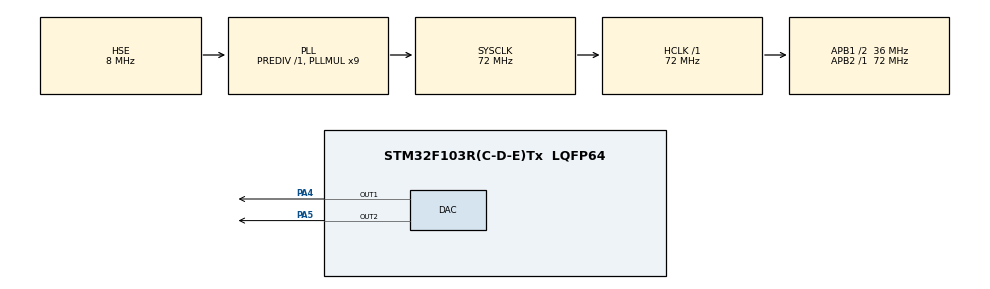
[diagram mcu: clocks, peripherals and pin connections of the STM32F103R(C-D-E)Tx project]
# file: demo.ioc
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Mcu.Family=STM32F1
Mcu.Name=STM32F103R(C-D-E)Tx
Mcu.Package=LQFP64
NVIC.PriorityGroup=NVIC_PRIORITYGROUP_4
PA13.Mode=Serial_Wire
PA13.Signal=SYS_JTMS-SWDIO
PA14.Mode=Serial_Wire
PA14.Signal=SYS_JTCK-SWCLK
PA4.Signal=COMP_DAC1_group
PA5.Signal=COMP_DAC2_group
PD0-OSC_IN.Mode=HSE-External-Oscillator
PD0-OSC_IN.Signal=RCC_OSC_IN
PD1-OSC_OUT.Mode=HSE-External-Oscillator
PD1-OSC_OUT.Signal=RCC_OSC_OUT
ProjectManager.HeapSize=0x200
ProjectManager.StackSize=0x400
ProjectManager.TargetToolchain=MDK-ARM V5
RCC.AHBFreq_Value=72000000
RCC.APB1CLKDivider=RCC_HCLK_DIV2
RCC.APB1Freq_Value=36000000
RCC.APB1TimFreq_Value=72000000
RCC.APB2Freq_Value=72000000
RCC.APB2TimFreq_Value=72000000
RCC.HCLKFreq_Value=72000000
RCC.PLLMUL=RCC_PLL_MUL9
RCC.PLLSourceVirtual=RCC_PLLSOURCE_HSE
RCC.SYSCLKFreq_VALUE=72000000
RCC.SYSCLKSource=RCC_SYSCLKSOURCE_PLLCLK
RCC.USBFreq_Value=72000000
SH.COMP_DAC1_group.0=DAC_OUT1,DAC_OUT1
SH.COMP_DAC2_group.0=DAC_OUT2,DAC_OUT2
board=custom

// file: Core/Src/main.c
/* USER CODE BEGIN Header */
/**
 ******************************************************************************
 * @file           : main.c
 * @brief          : Main program body
 ******************************************************************************
 * @attention
 *
 * <h2><center>&copy; Copyright (c) 2022 STMicroelectronics.
 * All rights reserved.</center></h2>
 *
 * This software component is licensed by ST under BSD 3-Clause license,
 * the "License"; You may not use this file except in compliance with the
 * License. You may obtain a copy of the License at:
 *                        opensource.org/licenses/BSD-3-Clause
 *
 ******************************************************************************
 */
/* USER CODE END Header */
#include "main.h"
#include "dac.h"
#include "gpio.h"

void SystemClock_Config(void);

/* USER CODE BEGIN 0 */

#if 0

// string

static const uint8_t xs[] = {
    2, 2, 22, 22, 2, 22,                     // R
    27, 48, 48, 27, 27, 27, 48, 48, 27, 48,  // 2
    52, 52, 73, 73, 52, 73, 73,              // A
    85, 77, 77, 77, 85, 91, 98, 98, 98, 91,  // U
    102, 102, 102, 123, 102, 123,            // K
};
static const uint8_t ys[] = {
    42, 84, 84, 63, 63, 42,                  // R
    42, 63, 84, 84, 63, 84, 84, 63, 42, 42,  // 2
    42, 84, 84, 63, 63, 63, 42,              // A
    42, 50, 84, 50, 42, 42, 50, 84, 50, 42,  // U
    42, 84, 63, 84, 63, 42,                  // K
};

int16_t idx       = 0;
int16_t prev_idx  = 0;
uint8_t curr_x    = 0;
uint8_t curr_y    = 0;
int16_t dx        = 0;
int16_t dy        = 0;
int8_t  direction = 1;

void next_line()
{
    const uint8_t speed          = 32;
    int8_t        next_direction = direction;
    idx += direction;
    if (idx < 0) {
        idx            = 0;
        next_direction = -direction;
    } else if (idx >= sizeof(xs) / sizeof(xs[0])) {
        idx            = sizeof(xs) / sizeof(xs[0]) - 1;
        next_direction = -direction;
    }

    prev_idx = idx - direction;
    if (prev_idx < 0) {
        prev_idx = sizeof(xs) / sizeof(xs[0]) - 1;
    } else if (prev_idx >= sizeof(xs) / sizeof(xs[0])) {
        prev_idx = 0;
    }

    direction = next_direction;
    curr_x    = xs[prev_idx];
    curr_y    = ys[prev_idx];

    dx        = (((int16_t)xs[idx]) - ((int16_t)xs[prev_idx])) / speed;
    dy        = (((int16_t)ys[idx]) - ((int16_t)ys[prev_idx])) / speed;
    if (dx == 0) {
        if (xs[idx] > xs[prev_idx]) {
            dx = 1;
        } else if (xs[idx] < xs[prev_idx]) {
            dx = -1;
        }
    }

    if (dy == 0) {
        if (ys[idx] > ys[prev_idx]) {
            dy = 1;
        } else if (ys[idx] < ys[prev_idx]) {
            dy = -1;
        }
    }
}

void init()
{
    HAL_DAC_Start(&hdac, DAC_CHANNEL_1);
    HAL_DAC_Start(&hdac, DAC_CHANNEL_2);
    next_line();
    HAL_Delay(1);
}

void loop()
{
    curr_x += dx;
    curr_y += dy;
    if (((dx > 0) && (curr_x > xs[idx])) ||
        ((dx < 0) && (curr_x < xs[idx]))) {
        curr_x = xs[idx];
    }
    if (((dy > 0) && (curr_y > ys[idx])) ||
        ((dy < 0) && (curr_y < ys[idx]))) {
        curr_y = ys[idx];
    }

    uint32_t x = ((uint32_t)curr_x) * 0xFFF / 128;
    uint32_t y = ((uint32_t)curr_y) * 0xFFF / 128;
    HAL_DAC_SetValue(&hdac, DAC_CHANNEL_1, DAC_ALIGN_12B_R, x);
    HAL_DAC_SetValue(&hdac, DAC_CHANNEL_2, DAC_ALIGN_12B_R, y);

    if ((curr_x == xs[idx]) && (curr_y == ys[idx])) {
        next_line();
    }

    HAL_Delay(10);
}

#else

// image

#define ARRAY_SIZE(arr) (sizeof(arr) / sizeof(arr[0]))

static const uint16_t img[3832] = {
    976, 3147, 995, 3147, 1013, 3147, 1032, 3147, 1050, 3147,
    1069, 3147, 1087, 3147, 1105, 3147, 1124, 3147, 1142, 3147,
    1161, 3147, 1179, 3147, 1198, 3147, 1216, 3147, 1235, 3147,
    1253, 3147, 1271, 3147, 1290, 3147, 1308, 3147, 1327, 3147,
    1345, 3147, 1364, 3147, 1382, 3147, 1400, 3147, 1419, 3147,
    1437, 3147, 1456, 3147, 1474, 3147, 1493, 3147, 1511, 3147,
    1529, 3147, 1548, 3147, 1566, 3147, 1585, 3147, 1603, 3147,
    1622, 3147, 1640, 3147, 1658, 3147, 1677, 3147, 1695, 3147,
    1714, 3147, 1732, 3147, 1751, 3147, 1769, 3147, 1788, 3147,
    1806, 3147, 1824, 3147, 1843, 3147, 1861, 3147, 1880, 3147,
    1898, 3147, 1917, 3147, 1935, 3147, 1953, 3147, 1972, 3147,
    1990, 3147, 2009, 3147, 2027, 3147, 2046, 3147, 2064, 3147,
    2082, 3147, 2101, 3147, 2119, 3147, 2138, 3147, 2156, 3147,
    2175, 3147, 2193, 3147, 2211, 3147, 2230, 3147, 2248, 3147,
    2267, 3147, 2285, 3147, 2304, 3147, 2322, 3147, 2341, 3147,
    2359, 3147, 2377, 3147, 2396, 3147, 2414, 3147, 2433, 3147,
    2451, 3147, 2470, 3147, 2488, 3147, 2506, 3147, 2525, 3147,
    2543, 3147, 2562, 3147, 2580, 3147, 2599, 3147, 2617, 3147,
    2635, 3147, 2654, 3147, 2672, 3147, 2691, 3147, 2709, 3147,
    2728, 3147, 2746, 3147, 2764, 3147, 2783, 3147, 2801, 3147,
    2820, 3147, 2838, 3147, 2857, 3147, 2875, 3147, 2894, 3147,
    2912, 3147, 2930, 3147, 2949, 3147, 2967, 3147, 2986, 3147,
    3004, 3147, 3023, 3147, 3041, 3147, 3059, 3147, 3078, 3147,
    3096, 3147, 958, 3122, 3115, 3122, 940, 3098, 3115, 3098,
    940, 3074, 3115, 3074, 940, 3049, 1087, 3049, 1105, 3049,
    1124, 3049, 1142, 3049, 1161, 3049, 1179, 3049, 1198, 3049,
    1216, 3049, 1235, 3049, 1253, 3049, 1271, 3049, 1290, 3049,
    1308, 3049, 1327, 3049, 1345, 3049, 1364, 3049, 1382, 3049,
    1400, 3049, 1419, 3049, 1437, 3049, 1456, 3049, 1474, 3049,
    1493, 3049, 1511, 3049, 1529, 3049, 1548, 3049, 1566, 3049,
    1585, 3049, 1603, 3049, 1622, 3049, 1640, 3049, 1658, 3049,
    1677, 3049, 1695, 3049, 1714, 3049, 1732, 3049, 1751, 3049,
    1769, 3049, 1788, 3049, 1806, 3049, 1824, 3049, 1843, 3049,
    1861, 3049, 1880, 3049, 1898, 3049, 1917, 3049, 1935, 3049,
    1953, 3049, 1972, 3049, 1990, 3049, 2009, 3049, 2027, 3049,
    2046, 3049, 2064, 3049, 2082, 3049, 2101, 3049, 2119, 3049,
    2138, 3049, 2156, 3049, 2175, 3049, 2193, 3049, 2211, 3049,
    2230, 3049, 2248, 3049, 2267, 3049, 2285, 3049, 2304, 3049,
    2322, 3049, 2341, 3049, 2359, 3049, 2377, 3049, 2396, 3049,
    2414, 3049, 2433, 3049, 2451, 3049, 2470, 3049, 2488, 3049,
    2506, 3049, 2525, 3049, 2543, 3049, 2562, 3049, 2580, 3049,
    2599, 3049, 2617, 3049, 2635, 3049, 2654, 3049, 2672, 3049,
    2691, 3049, 2709, 3049, 2728, 3049, 2746, 3049, 2764, 3049,
    2783, 3049, 2801, 3049, 2820, 3049, 2838, 3049, 2857, 3049,
    2875, 3049, 2894, 3049, 2912, 3049, 2930, 3049, 2949, 3049,
    2967, 3049, 2986, 3049, 3004, 3049, 3115, 3049, 940, 3025,
    1069, 3025, 3023, 3025, 3115, 3025, 940, 3000, 1050, 3000,
    3023, 3000, 3115, 3000, 940, 2976, 1050, 2976, 3023, 2976,
    3115, 2976, 940, 2952, 1050, 2952, 3023, 2952, 3115, 2952,
    940, 2927, 1050, 2927, 1179, 2927, 1198, 2927, 1216, 2927,
    1235, 2927, 1253, 2927, 1271, 2927, 1290, 2927, 1308, 2927,
    1327, 2927, 1345, 2927, 1364, 2927, 1382, 2927, 1400, 2927,
    1419, 2927, 1437, 2927, 1456, 2927, 1474, 2927, 1493, 2927,
    1511, 2927, 1529, 2927, 1548, 2927, 1566, 2927, 1585, 2927,
    1603, 2927, 1622, 2927, 1640, 2927, 1658, 2927, 1677, 2927,
    1695, 2927, 1714, 2927, 1732, 2927, 1751, 2927, 1769, 2927,
    1788, 2927, 1806, 2927, 1824, 2927, 1843, 2927, 1861, 2927,
    1880, 2927, 1898, 2927, 1917, 2927, 1935, 2927, 1953, 2927,
    1972, 2927, 1990, 2927, 2009, 2927, 2027, 2927, 2046, 2927,
    2064, 2927, 2082, 2927, 2101, 2927, 2119, 2927, 2138, 2927,
    2156, 2927, 2175, 2927, 2193, 2927, 2211, 2927, 2230, 2927,
    2248, 2927, 2267, 2927, 2285, 2927, 2304, 2927, 2322, 2927,
    2341, 2927, 2359, 2927, 2377, 2927, 2396, 2927, 2414, 2927,
    2433, 2927, 2451, 2927, 2470, 2927, 2488, 2927, 2506, 2927,
    2525, 2927, 2543, 2927, 2562, 2927, 2580, 2927, 2599, 2927,
    2617, 2927, 2635, 2927, 2654, 2927, 2672, 2927, 2691, 2927,
    2709, 2927, 2728, 2927, 2746, 2927, 2764, 2927, 2783, 2927,
    2801, 2927, 2820, 2927, 2838, 2927, 2857, 2927, 2875, 2927,
    2894, 2927, 2912, 2927, 3023, 2927, 3115, 2927, 940, 2903,
    1050, 2903, 1161, 2903, 2930, 2903, 3023, 2903, 3115, 2903,
    940, 2879, 1050, 2879, 1142, 2879, 2930, 2879, 3023, 2879,
    3115, 2879, 940, 2854, 1050, 2854, 1142, 2854, 2930, 2854,
    3023, 2854, 3115, 2854, 940, 2830, 1050, 2830, 1142, 2830,
    2930, 2830, 3023, 2830, 3115, 2830, 940, 2805, 1050, 2805,
    1142, 2805, 2930, 2805, 3023, 2805, 3115, 2805, 940, 2781,
    1050, 2781, 1142, 2781, 2930, 2781, 3023, 2781, 3115, 2781,
    940, 2757, 1050, 2757, 1142, 2757, 2930, 2757, 3023, 2757,
    3115, 2757, 940, 2732, 1050, 2732, 1142, 2732, 1953, 2732,
    1972, 2732, 1990, 2732, 2009, 2732, 2027, 2732, 2046, 2732,
    2064, 2732, 2082, 2732, 2101, 2732, 2119, 2732, 2930, 2732,
    3023, 2732, 3115, 2732, 940, 2708, 1050, 2708, 1142, 2708,
    1861, 2708, 1880, 2708, 1898, 2708, 1917, 2708, 1935, 2708,
    2138, 2708, 2156, 2708, 2175, 2708, 2193, 2708, 2211, 2708,
    2230, 2708, 2930, 2708, 3023, 2708, 3115, 2708, 940, 2683,
    1050, 2683, 1142, 2683, 1769, 2683, 1788, 2683, 1806, 2683,
    1824, 2683, 1843, 2683, 2248, 2683, 2267, 2683, 2285, 2683,
    2304, 2683, 2930, 2683, 3023, 2683, 3115, 2683, 940, 2659,
    1050, 2659, 1142, 2659, 1732, 2659, 1751, 2659, 2322, 2659,
    2341, 2659, 2930, 2659, 3023, 2659, 3115, 2659, 940, 2635,
    1050, 2635, 1142, 2635, 1677, 2635, 1695, 2635, 1714, 2635,
    2359, 2635, 2377, 2635, 2396, 2635, 2930, 2635, 3023, 2635,
    3115, 2635, 940, 2610, 1050, 2610, 1142, 2610, 1640, 2610,
    1658, 2610, 1935, 2610, 1953, 2610, 1972, 2610, 1990, 2610,
    2009, 2610, 2027, 2610, 2046, 2610, 2064, 2610, 2082, 2610,
    2101, 2610, 2119, 2610, 2138, 2610, 2414, 2610, 2433, 2610,
    2930, 2610, 3023, 2610, 3115, 2610, 940, 2586, 1050, 2586,
    1142, 2586, 1603, 2586, 1622, 2586, 1861, 2586, 1880, 2586,
    1898, 2586, 1917, 2586, 2156, 2586, 2175, 2586, 2193, 2586,
    2211, 2586, 2451, 2586, 2470, 2586, 2930, 2586, 3023, 2586,
    3115, 2586, 940, 2561, 1050, 2561, 1142, 2561, 1585, 2561,
    1603, 2561, 1788, 2561, 1806, 2561, 1824, 2561, 1843, 2561,
    2230, 2561, 2248, 2561, 2267, 2561, 2285, 2561, 2470, 2561,
    2488, 2561, 2930, 2561, 3023, 2561, 3115, 2561, 940, 2537,
    1050, 2537, 1142, 2537, 1548, 2537, 1566, 2537, 1751, 2537,
    1769, 2537, 2304, 2537, 2322, 2537, 2506, 2537, 2525, 2537,
    2930, 2537, 3023, 2537, 3115, 2537, 940, 2513, 1050, 2513,
    1142, 2513, 1529, 2513, 1548, 2513, 1714, 2513, 1732, 2513,
    2341, 2513, 2359, 2513, 2377, 2513, 2525, 2513, 2543, 2513,
    2930, 2513, 3023, 2513, 3115, 2513, 940, 2488, 1050, 2488,
    1142, 2488, 1493, 2488, 1511, 2488, 1677, 2488, 1695, 2488,
    2396, 2488, 2414, 2488, 2562, 2488, 2580, 2488, 2930, 2488,
    3023, 2488, 3115, 2488, 940, 2464, 1050, 2464, 1142, 2464,
    1474, 2464, 1493, 2464, 1640, 2464, 1658, 2464, 2414, 2464,
    2433, 2464, 2580, 2464, 2599, 2464, 2930, 2464, 3023, 2464,
    3115, 2464, 940, 2440, 1050, 2440, 1142, 2440, 1456, 2440,
    1474, 2440, 1603, 2440, 1622, 2440, 2451, 2440, 2470, 2440,
    2599, 2440, 2617, 2440, 2930, 2440, 3023, 2440, 3115, 2440,
    940, 2415, 1050, 2415, 1142, 2415, 1437, 2415, 1456, 2415,
    1585, 2415, 1603, 2415, 2470, 2415, 2488, 2415, 2617, 2415,
    2635, 2415, 2930, 2415, 3023, 2415, 3115, 2415, 940, 2391,
    1050, 2391, 1142, 2391, 1419, 2391, 1437, 2391, 1548, 2391,
    1566, 2391, 2506, 2391, 2525, 2391, 2635, 2391, 2654, 2391,
    2930, 2391, 3023, 2391, 3115, 2391, 940, 2366, 1050, 2366,
    1142, 2366, 1419, 2366, 1529, 2366, 1548, 2366, 2525, 2366,
    2543, 2366, 2654, 2366, 2672, 2366, 2930, 2366, 3023, 2366,
    3115, 2366, 940, 2342, 1050, 2342, 1142, 2342, 1400, 2342,
    1511, 2342, 1529, 2342, 2543, 2342, 2562, 2342, 2672, 2342,
    2930, 2342, 3023, 2342, 3115, 2342, 940, 2318, 1050, 2318,
    1142, 2318, 1382, 2318, 1400, 2318, 1493, 2318, 1511, 2318,
    2562, 2318, 2580, 2318, 2691, 2318, 2930, 2318, 3023, 2318,
    3115, 2318, 940, 2293, 1050, 2293, 1142, 2293, 1364, 2293,
    1382, 2293, 1493, 2293, 2580, 2293, 2691, 2293, 2709, 2293,
    2930, 2293, 3023, 2293, 3115, 2293, 940, 2269, 1050, 2269,
    1142, 2269, 1364, 2269, 1474, 2269, 2599, 2269, 2709, 2269,
    2930, 2269, 3023, 2269, 3115, 2269, 940, 2244, 1050, 2244,
    1142, 2244, 1345, 2244, 1456, 2244, 1474, 2244, 2599, 2244,
    2617, 2244, 2709, 2244, 2930, 2244, 3023, 2244, 3115, 2244,
    940, 2220, 1050, 2220, 1142, 2220, 1345, 2220, 1456, 2220,
    2617, 2220, 2728, 2220, 2930, 2220, 3023, 2220, 3115, 2220,
    940, 2196, 1050, 2196, 1142, 2196, 1345, 2196, 1437, 2196,
    2635, 2196, 2728, 2196, 2930, 2196, 3023, 2196, 3115, 2196,
    940, 2171, 1050, 2171, 1142, 2171, 1327, 2171, 1437, 2171,
    2635, 2171, 2746, 2171, 2930, 2171, 3023, 2171, 3115, 2171,
    940, 2147, 1050, 2147, 1142, 2147, 1327, 2147, 1419, 2147,
    2654, 2147, 2746, 2147, 2930, 2147, 3023, 2147, 3115, 2147,
    940, 2122, 1050, 2122, 1142, 2122, 1308, 2122, 1419, 2122,
    2654, 2122, 2746, 2122, 2930, 2122, 3023, 2122, 3115, 2122,
    940, 2098, 1050, 2098, 1142, 2098, 1308, 2098, 1400, 2098,
    2654, 2098, 2764, 2098, 2930, 2098, 3023, 2098, 3115, 2098,
    940, 2074, 1050, 2074, 1142, 2074, 1308, 2074, 1400, 2074,
    2672, 2074, 2764, 2074, 2930, 2074, 3023, 2074, 3115, 2074,
    940, 2049, 1050, 2049, 1142, 2049, 1308, 2049, 1400, 2049,
    2672, 2049, 2764, 2049, 2930, 2049, 3023, 2049, 3115, 2049,
    940, 2025, 1050, 2025, 1142, 2025, 1290, 2025, 1382, 2025,
    2672, 2025, 2764, 2025, 2930, 2025, 3023, 2025, 3115, 2025,
    940, 2000, 1050, 2000, 1142, 2000, 1290, 2000, 1382, 2000,
    2672, 2000, 2764, 2000, 2930, 2000, 3023, 2000, 3115, 2000,
    940, 1976, 1050, 1976, 1142, 1976, 1290, 1976, 1382, 1976,
    2672, 1976, 2764, 1976, 2930, 1976, 3023, 1976, 3115, 1976,
    940, 1952, 1050, 1952, 1142, 1952, 1290, 1952, 1382, 1952,
    2672, 1952, 2764, 1952, 2930, 1952, 3023, 1952, 3115, 1952,
    940, 1927, 1050, 1927, 1142, 1927, 1290, 1927, 1382, 1927,
    2672, 1927, 2764, 1927, 2930, 1927, 3023, 1927, 3115, 1927,
    940, 1903, 1050, 1903, 1142, 1903, 1290, 1903, 1382, 1903,
    2672, 1903, 2764, 1903, 2930, 1903, 3023, 1903, 3115, 1903,
    940, 1879, 1050, 1879, 1142, 1879, 1290, 1879, 1400, 1879,
    2672, 1879, 2764, 1879, 2930, 1879, 3023, 1879, 3115, 1879,
    940, 1854, 1050, 1854, 1142, 1854, 1308, 1854, 1400, 1854,
    2672, 1854, 2764, 1854, 2930, 1854, 3023, 1854, 3115, 1854,
    940, 1830, 1050, 1830, 1142, 1830, 1308, 1830, 1400, 1830,
    2654, 1830, 2764, 1830, 2930, 1830, 3023, 1830, 3115, 1830,
    940, 1805, 1050, 1805, 1142, 1805, 1308, 1805, 1419, 1805,
    2654, 1805, 2746, 1805, 2930, 1805, 3023, 1805, 3115, 1805,
    940, 1781, 1050, 1781, 1142, 1781, 1327, 1781, 1419, 1781,
    2654, 1781, 2746, 1781, 2930, 1781, 3023, 1781, 3115, 1781,
    940, 1757, 1050, 1757, 1142, 1757, 1327, 1757, 1437, 1757,
    2635, 1757, 2746, 1757, 2930, 1757, 3023, 1757, 3115, 1757,
    940, 1732, 1050, 1732, 1142, 1732, 1327, 1732, 1437, 1732,
    2635, 1732, 2728, 1732, 2930, 1732, 3023, 1732, 3115, 1732,
    940, 1708, 1050, 1708, 1142, 1708, 1345, 1708, 1456, 1708,
    2617, 1708, 2635, 1708, 2728, 1708, 2930, 1708, 3023, 1708,
    3115, 1708, 940, 1683, 1050, 1683, 1142, 1683, 1345, 1683,
    1456, 1683, 1474, 1683, 2617, 1683, 2728, 1683, 2930, 1683,
    3023, 1683, 3115, 1683, 940, 1659, 1050, 1659, 1142, 1659,
    1364, 1659, 1474, 1659, 2599, 1659, 2709, 1659, 2930, 1659,
    3023, 1659, 3115, 1659, 940, 1635, 1050, 1635, 1142, 1635,
    1364, 1635, 1382, 1635, 1493, 1635, 2580, 1635, 2599, 1635,
    2691, 1635, 2709, 1635, 2930, 1635, 3023, 1635, 3115, 1635,
    940, 1610, 1050, 1610, 1142, 1610, 1382, 1610, 1400, 1610,
    1493, 1610, 1511, 1610, 2562, 1610, 2580, 1610, 2691, 1610,
    2930, 1610, 3023, 1610, 3115, 1610, 940, 1586, 1050, 1586,
    1142, 1586, 1400, 1586, 1511, 1586, 1529, 1586, 2543, 1586,
    2562, 1586, 2672, 1586, 2930, 1586, 3023, 1586, 3115, 1586,
    940, 1561, 1050, 1561, 1142, 1561, 1419, 1561, 1529, 1561,
    1548, 1561, 2525, 1561, 2543, 1561, 2654, 1561, 2672, 1561,
    2930, 1561, 3023, 1561, 3115, 1561, 940, 1537, 1050, 1537,
    1142, 1537, 1419, 1537, 1437, 1537, 1548, 1537, 1566, 1537,
    2506, 1537, 2525, 1537, 2635, 1537, 2654, 1537, 2930, 1537,
    3023, 1537, 3115, 1537, 940, 1513, 1050, 1513, 1142, 1513,
    1437, 1513, 1456, 1513, 1585, 1513, 1603, 1513, 2488, 1513,
    2506, 1513, 2617, 1513, 2635, 1513, 2930, 1513, 3023, 1513,
    3115, 1513, 940, 1488, 1050, 1488, 1142, 1488, 1456, 1488,
    1474, 1488, 1603, 1488, 1622, 1488, 2451, 1488, 2470, 1488,
    2599, 1488, 2617, 1488, 2930, 1488, 3023, 1488, 3115, 1488,
    940, 1464, 1050, 1464, 1142, 1464, 1474, 1464, 1493, 1464,
    1640, 1464, 1658, 1464, 2414, 1464, 2433, 1464, 2580, 1464,
    2599, 1464, 2930, 1464, 3023, 1464, 3115, 1464, 940, 1440,
    1050, 1440, 1142, 1440, 1493, 1440, 1511, 1440, 1677, 1440,
    1695, 1440, 2377, 1440, 2396, 1440, 2414, 1440, 2562, 1440,
    2580, 1440, 2930, 1440, 3023, 1440, 3115, 1440, 940, 1415,
    1050, 1415, 1142, 1415, 1511, 1415, 1529, 1415, 1714, 1415,
    1732, 1415, 2341, 1415, 2359, 1415, 2543, 1415, 2562, 1415,
    2930, 1415, 3023, 1415, 3115, 1415, 940, 1391, 1050, 1391,
    1142, 1391, 1548, 1391, 1566, 1391, 1751, 1391, 1769, 1391,
    1788, 1391, 1806, 1391, 2267, 1391, 2285, 1391, 2304, 1391,
    2322, 1391, 2506, 1391, 2525, 1391, 2930, 1391, 3023, 1391,
    3115, 1391, 940, 1366, 1050, 1366, 1142, 1366, 1585, 1366,
    1603, 1366, 1824, 1366, 1843, 1366, 1861, 1366, 1880, 1366,
    2193, 1366, 2211, 1366, 2230, 1366, 2248, 1366, 2470, 1366,
    2488, 1366, 2930, 1366, 3023, 1366, 3115, 1366, 940, 1342,
    1050, 1342, 1142, 1342, 1603, 1342, 1622, 1342, 1898, 1342,
    1917, 1342, 1935, 1342, 1953, 1342, 1972, 1342, 1990, 1342,
    2009, 1342, 2027, 1342, 2046, 1342, 2064, 1342, 2082, 1342,
    2101, 1342, 2119, 1342, 2138, 1342, 2156, 1342, 2175, 1342,
    2451, 1342, 2470, 1342, 2930, 1342, 3023, 1342, 3115, 1342,
    940, 1318, 1050, 1318, 1142, 1318, 1640, 1318, 1658, 1318,
    1677, 1318, 2396, 1318, 2414, 1318, 2433, 1318, 2930, 1318,
    3023, 1318, 3115, 1318, 940, 1293, 1050, 1293, 1142, 1293,
    1695, 1293, 1714, 1293, 2359, 1293, 2377, 1293, 2930, 1293,
    3023, 1293, 3115, 1293, 940, 1269, 1050, 1269, 1142, 1269,
    1732, 1269, 1751, 1269, 1769, 1269, 1788, 1269, 2285, 1269,
    2304, 1269, 2322, 1269, 2341, 1269, 2930, 1269, 3023, 1269,
    3115, 1269, 940, 1244, 1050, 1244, 1142, 1244, 1806, 1244,
    1824, 1244, 1843, 1244, 1861, 1244, 1880, 1244, 2193, 1244,
    2211, 1244, 2230, 1244, 2248, 1244, 2267, 1244, 2930, 1244,
    3023, 1244, 3115, 1244, 940, 1220, 1050, 1220, 1142, 1220,
    1898, 1220, 1917, 1220, 1935, 1220, 1953, 1220, 1972, 1220,
    1990, 1220, 2009, 1220, 2027, 1220, 2046, 1220, 2064, 1220,
    2082, 1220, 2101, 1220, 2119, 1220, 2138, 1220, 2156, 1220,
    2175, 1220, 2930, 1220, 3023, 1220, 3115, 1220, 940, 1196,
    1050, 1196, 1142, 1196, 2930, 1196, 3023, 1196, 3115, 1196,
    940, 1171, 1050, 1171, 1142, 1171, 2930, 1171, 3023, 1171,
    3115, 1171, 940, 1147, 1050, 1147, 1142, 1147, 2930, 1147,
    3023, 1147, 3115, 1147, 940, 1122, 1050, 1122, 1142, 1122,
    2930, 1122, 3023, 1122, 3115, 1122, 940, 1098, 1050, 1098,
    1142, 1098, 2930, 1098, 3023, 1098, 3115, 1098, 940, 1074,
    1050, 1074, 1142, 1074, 2930, 1074, 3023, 1074, 3115, 1074,
    940, 1049, 1050, 1049, 1161, 1049, 1179, 1049, 1198, 1049,
    1216, 1049, 1235, 1049, 1253, 1049, 1271, 1049, 1290, 1049,
    1308, 1049, 1327, 1049, 1345, 1049, 1364, 1049, 1382, 1049,
    1400, 1049, 1419, 1049, 1437, 1049, 1456, 1049, 1474, 1049,
    1493, 1049, 1511, 1049, 1529, 1049, 1548, 1049, 1566, 1049,
    1585, 1049, 1603, 1049, 1622, 1049, 1640, 1049, 1658, 1049,
    1677, 1049, 1695, 1049, 1714, 1049, 1732, 1049, 1751, 1049,
    1769, 1049, 1788, 1049, 1806, 1049, 1824, 1049, 1843, 1049,
    1861, 1049, 1880, 1049, 1898, 1049, 1917, 1049, 1935, 1049,
    1953, 1049, 1972, 1049, 1990, 1049, 2009, 1049, 2027, 1049,
    2046, 1049, 2064, 1049, 2082, 1049, 2101, 1049, 2119, 1049,
    2138, 1049, 2156, 1049, 2175, 1049, 2193, 1049, 2211, 1049,
    2230, 1049, 2248, 1049, 2267, 1049, 2285, 1049, 2304, 1049,
    2322, 1049, 2341, 1049, 2359, 1049, 2377, 1049, 2396, 1049,
    2414, 1049, 2433, 1049, 2451, 1049, 2470, 1049, 2488, 1049,
    2506, 1049, 2525, 1049, 2543, 1049, 2562, 1049, 2580, 1049,
    2599, 1049, 2617, 1049, 2635, 1049, 2654, 1049, 2672, 1049,
    2691, 1049, 2709, 1049, 2728, 1049, 2746, 1049, 2764, 1049,
    2783, 1049, 2801, 1049, 2820, 1049, 2838, 1049, 2857, 1049,
    2875, 1049, 2894, 1049, 2912, 1049, 2930, 1049, 3023, 1049,
    3115, 1049, 940, 1025, 1050, 1025, 3023, 1025, 3115, 1025,
    940, 1000, 1050, 1000, 3023, 1000, 3115, 1000, 940, 976,
    1050, 976, 3023, 976, 3115, 976, 940, 952, 1050, 952,
    3023, 952, 3115, 952, 940, 927, 1069, 927, 1087, 927,
    1105, 927, 1124, 927, 1142, 927, 1161, 927, 1179, 927,
    1198, 927, 1216, 927, 1235, 927, 1253, 927, 1271, 927,
    1290, 927, 1308, 927, 1327, 927, 1345, 927, 1364, 927,
    1382, 927, 1400, 927, 1419, 927, 1437, 927, 1456, 927,
    1474, 927, 1493, 927, 1511, 927, 1529, 927, 1548, 927,
    1566, 927, 1585, 927, 1603, 927, 1622, 927, 1640, 927,
    1658, 927, 1677, 927, 1695, 927, 1714, 927, 1732, 927,
    1751, 927, 1769, 927, 1788, 927, 1806, 927, 1824, 927,
    1843, 927, 1861, 927, 1880, 927, 1898, 927, 1917, 927,
    1935, 927, 1953, 927, 1972, 927, 1990, 927, 2009, 927,
    2027, 927, 2046, 927, 2064, 927, 2082, 927, 2101, 927,
    2119, 927, 2138, 927, 2156, 927, 2175, 927, 2193, 927,
    2211, 927, 2230, 927, 2248, 927, 2267, 927, 2285, 927,
    2304, 927, 2322, 927, 2341, 927, 2359, 927, 2377, 927,
    2396, 927, 2414, 927, 2433, 927, 2451, 927, 2470, 927,
    2488, 927, 2506, 927, 2525, 927, 2543, 927, 2562, 927,
    2580, 927, 2599, 927, 2617, 927, 2635, 927, 2654, 927,
    2672, 927, 2691, 927, 2709, 927, 2728, 927, 2746, 927,
    2764, 927, 2783, 927, 2801, 927, 2820, 927, 2838, 927,
    2857, 927, 2875, 927, 2894, 927, 2912, 927, 2930, 927,
    2949, 927, 2967, 927, 2986, 927, 3004, 927, 3023, 927,
    3115, 927, 940, 903, 3115, 903, 940, 879, 3115, 879,
    940, 854, 3115, 854, 940, 830, 3115, 830, 958, 805,
    976, 805, 995, 805, 1013, 805, 1032, 805, 1050, 805,
    1069, 805, 1087, 805, 1105, 805, 1124, 805, 1142, 805,
    1161, 805, 1179, 805, 1198, 805, 1216, 805, 1235, 805,
    1253, 805, 1271, 805, 1290, 805, 1308, 805, 1327, 805,
    1345, 805, 1364, 805, 1382, 805, 1400, 805, 1419, 805,
    1437, 805, 1456, 805, 1474, 805, 1493, 805, 1511, 805,
    1529, 805, 1548, 805, 1566, 805, 1585, 805, 1603, 805,
    1622, 805, 1640, 805, 1658, 805, 1677, 805, 1695, 805,
    1714, 805, 1732, 805, 1751, 805, 1769, 805, 1788, 805,
    1806, 805, 1824, 805, 1843, 805, 1861, 805, 1880, 805,
    1898, 805, 1917, 805, 1935, 805, 1953, 805, 1972, 805,
    1990, 805, 2009, 805, 2027, 805, 2046, 805, 2064, 805,
    2082, 805, 2101, 805, 2119, 805, 2138, 805, 2156, 805,
    2175, 805, 2193, 805, 2211, 805, 2230, 805, 2248, 805,
    2267, 805, 2285, 805, 2304, 805, 2322, 805, 2341, 805,
    2359, 805, 2377, 805, 2396, 805, 2414, 805, 2433, 805,
    2451, 805, 2470, 805, 2488, 805, 2506, 805, 2525, 805,
    2543, 805, 2562, 805, 2580, 805, 2599, 805, 2617, 805,
    2635, 805, 2654, 805, 2672, 805, 2691, 805, 2709, 805,
    2728, 805, 2746, 805, 2764, 805, 2783, 805, 2801, 805,
    2820, 805, 2838, 805, 2857, 805, 2875, 805, 2894, 805,
    2912, 805, 2930, 805, 2949, 805, 2967, 805, 2986, 805,
    3004, 805, 3023, 805, 3041, 805, 3059, 805, 3078, 805,
    3096, 805, 3115, 805, 2377, 659, 2396, 659, 2414, 659,
    2433, 659, 2451, 659, 2470, 659, 2488, 659, 2506, 659,
    2525, 659, 2543, 659, 2562, 659, 2580, 659, 2599, 659,
    2617, 659, 2635, 659, 2654, 659, 2672, 659, 2691, 659,
    2709, 659, 2728, 659, 2746, 659, 2764, 659, 2783, 659,
    2801, 659, 2820, 659, 2838, 659, 2857, 659, 2875, 659,
    2894, 659, 2912, 659, 2930, 659, 2949, 659, 2967, 659,
    2986, 659, 3004, 659, 3023, 659, 3041, 659, 3059, 659,
    3078, 659, 3096, 659, 3115, 659, 3133, 659, 3152, 659,
    3170, 659, 3188, 659, 3207, 659, 3225, 659, 3244, 659,
    3262, 659, 3281, 659, 3299, 659, 3317, 659, 3336, 659,
    3354, 659, 3373, 659, 3391, 659, 3410, 659, 3428, 659,
    3447, 659, 3465, 659, 3483, 659, 3502, 659, 3520, 659,
    3539, 659, 3557, 659, 3576, 659, 3594, 659, 3612, 659,
    3631, 659, 3649, 659, 3668, 659, 3686, 659, 3705, 659,
    3723, 659, 3741, 659, 3760, 659, 3778, 659, 3797, 659,
    3815, 659, 3834, 659, 3852, 659, 3870, 659, 3889, 659,
    3907, 659, 3926, 659, 3944, 659, 3963, 659, 3981, 659,
    2359, 635, 2341, 610, 2341, 586, 2341, 561, 2341, 537,
    2341, 513, 2341, 488, 2341, 464, 2341, 440, 2341, 415,
    2341, 391, 2341, 366, 2341, 342, 2341, 318, 2341, 293,
    2341, 269, 2341, 244, 2341, 220, 2341, 196, 2341, 171,
    2341, 147, 2341, 122, 2341, 98, 2341, 74, 0, 49,
    18, 49, 36, 49, 55, 49, 73, 49, 92, 49,
    110, 49, 129, 49, 147, 49, 165, 49, 184, 49,
    202, 49, 221, 49, 239, 49, 258, 49, 276, 49,
    294, 49, 313, 49, 331, 49, 350, 49, 368, 49,
    387, 49, 405, 49, 423, 49, 442, 49, 460, 49,
    479, 49, 497, 49, 516, 49, 534, 49, 552, 49,
    571, 49, 589, 49, 608, 49, 626, 49, 645, 49,
    663, 49, 682, 49, 700, 49, 718, 49, 737, 49,
    755, 49, 774, 49, 792, 49, 811, 49, 829, 49,
    847, 49, 866, 49, 884, 49, 903, 49, 921, 49,
    940, 49, 958, 49, 976, 49, 995, 49, 1013, 49,
    1032, 49, 1050, 49, 1069, 49, 1087, 49, 1105, 49,
    1124, 49, 1142, 49, 1161, 49, 1179, 49, 1198, 49,
    1216, 49, 1235, 49, 1253, 49, 1271, 49, 1290, 49,
    1308, 49, 1327, 49, 1345, 49, 1364, 49, 1382, 49,
    1400, 49, 1419, 49, 1437, 49, 1456, 49, 1474, 49,
    1493, 49, 1511, 49, 1529, 49, 1548, 49, 1566, 49,
    1585, 49, 1603, 49, 1622, 49, 1640, 49, 1658, 49,
    1677, 49, 1695, 49, 1714, 49, 1732, 49, 1751, 49,
    1769, 49, 1788, 49, 1806, 49, 1824, 49, 1843, 49,
    1861, 49, 1880, 49, 1898, 49, 1917, 49, 1935, 49,
    1953, 49, 1972, 49, 1990, 49, 2009, 49, 2027, 49,
    2046, 49, 2064, 49, 2082, 49, 2101, 49, 2119, 49,
    2138, 49, 2156, 49, 2175, 49, 2193, 49, 2211, 49,
    2230, 49, 2248, 49, 2267, 49, 2285, 49, 2304, 49,
    2322, 49, 2341, 49, 2359, 49, 2377, 49, 2396, 49,
    2414, 49, 2433, 49, 2451, 49, 2470, 49, 2488, 49,
    2506, 49, 2525, 49, 2543, 49, 2562, 49, 2580, 49,
    2599, 49, 2617, 49, 2635, 49, 2654, 49, 2672, 49,
    2691, 49, 2709, 49, 2728, 49, 2746, 49, 2764, 49,
    2783, 49, 2801, 49, 2820, 49, 2838, 49, 2857, 49,
    2875, 49, 2894, 49, 2912, 49, 2930, 49, 2949, 49,
    2967, 49, 2986, 49, 3004, 49, 3023, 49, 3041, 49,
    3059, 49, 3078, 49, 3096, 49, 3115, 49, 3133, 49,
    3152, 49, 3170, 49, 3188, 49, 3207, 49, 3225, 49,
    3244, 49, 3262, 49, 3281, 49, 3299, 49, 3317, 49,
    3336, 49, 3354, 49, 3373, 49, 3391, 49, 3410, 49,
    3428, 49, 3447, 49, 3465, 49, 3483, 49, 3502, 49,
    3520, 49, 3539, 49, 3557, 49, 3576, 49, 3594, 49,
    3612, 49, 3631, 49, 3649, 49, 3668, 49, 3686, 49,
    3705, 49, 3723, 49, 3741, 49, 3760, 49, 3778, 49,
    3797, 49, 3815, 49, 3834, 49, 3852, 49, 3870, 49,
    3889, 49, 3907, 49, 3926, 49, 3944, 49, 3963, 49,
    3981, 49};

void init()
{
    HAL_DAC_Start(&hdac, DAC_CHANNEL_1);
    HAL_DAC_Start(&hdac, DAC_CHANNEL_2);
}

void loop()
{
    uint32_t i = 0;
    while (i < ARRAY_SIZE(img)) {
        DAC1->DHR12R1 = img[i++];
        DAC1->DHR12R2 = img[i++];
        HAL_Delay(8);  // 8us (自定)
    }
}

#endif

/* USER CODE END 0 */

int main(void)
{

    /* MCU Configuration--------------------------------------------------------*/

    /* Reset of all peripherals, Initializes the Flash interface and the Systick. */
    HAL_Init();

    /* Configure the system clock */
    SystemClock_Config();

    /* Initialize all configured peripherals */
    MX_GPIO_Init();
    MX_DAC_Init();
    /* USER CODE BEGIN 2 */
    init();
    /* USER CODE END 2 */

    /* Infinite loop */
    HAL_SYSTICK_Config(HAL_RCC_GetHCLKFreq() / 1e6);  // us
    /* USER CODE BEGIN WHILE */
    while (1) {
        loop();
        /* USER CODE END WHILE */

    }
}

void SystemClock_Config(void)
{
    RCC_OscInitTypeDef RCC_OscInitStruct = {0};
    RCC_ClkInitTypeDef RCC_ClkInitStruct = {0};

    /** Initializes the RCC Oscillators according to the specified parameters
     * in the RCC_OscInitTypeDef structure.
     */
    RCC_OscInitStruct.OscillatorType     = RCC_OSCILLATORTYPE_HSE;
    RCC_OscInitStruct.HSEState           = RCC_HSE_ON;
    RCC_OscInitStruct.HSEPredivValue     = RCC_HSE_PREDIV_DIV1;
    RCC_OscInitStruct.HSIState           = RCC_HSI_ON;
    RCC_OscInitStruct.PLL.PLLState       = RCC_PLL_ON;
    RCC_OscInitStruct.PLL.PLLSource      = RCC_PLLSOURCE_HSE;
    RCC_OscInitStruct.PLL.PLLMUL         = RCC_PLL_MUL9;
    if (HAL_RCC_OscConfig(&RCC_OscInitStruct) != HAL_OK) {
        Error_Handler();
    }

    /** Initializes the CPU, AHB and APB buses clocks
     */
    RCC_ClkInitStruct.ClockType      = RCC_CLOCKTYPE_HCLK | RCC_CLOCKTYPE_SYSCLK | RCC_CLOCKTYPE_PCLK1 | RCC_CLOCKTYPE_PCLK2;
    RCC_ClkInitStruct.SYSCLKSource   = RCC_SYSCLKSOURCE_PLLCLK;
    RCC_ClkInitStruct.AHBCLKDivider  = RCC_SYSCLK_DIV1;
    RCC_ClkInitStruct.APB1CLKDivider = RCC_HCLK_DIV2;
    RCC_ClkInitStruct.APB2CLKDivider = RCC_HCLK_DIV1;

    if (HAL_RCC_ClockConfig(&RCC_ClkInitStruct, FLASH_LATENCY_2) != HAL_OK) {
        Error_Handler();
    }
}

void Error_Handler(void)
{
}
